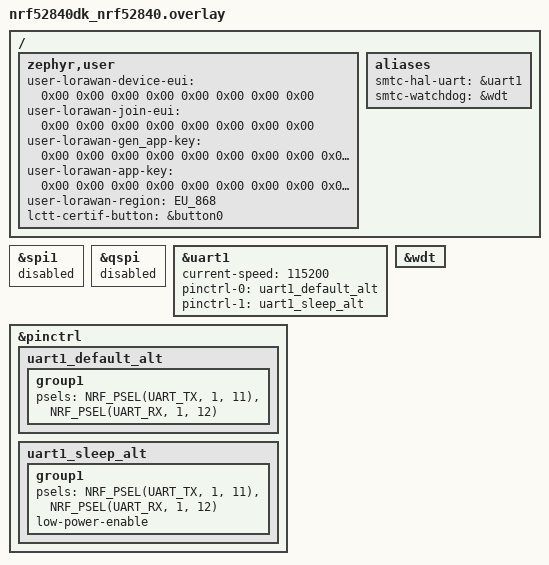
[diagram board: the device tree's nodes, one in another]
/*
 * Copyright (c) 2024 Semtech Corporation
 *
 * SPDX-License-Identifier: Apache-2.0
 */

/ {
    zephyr,user {
        user-lorawan-device-eui = <0x00 0x00 0x00 0x00 0x00 0x00 0x00 0x00>;
        user-lorawan-join-eui = <0x00 0x00 0x00 0x00 0x00 0x00 0x00 0x00>;
        user-lorawan-gen_app-key = <0x00 0x00 0x00 0x00 0x00 0x00 0x00 0x00 0x00 0x00 0x00 0x00 0x00 0x00 0x00 0x00>;
        user-lorawan-app-key = <0x00 0x00 0x00 0x00 0x00 0x00 0x00 0x00 0x00 0x00 0x00 0x00 0x00 0x00 0x00 0x00>;
        user-lorawan-region = "EU_868";

        /* PINS used for the sample. */
        lctt-certif-button = &button0;
    };

    aliases {
        /* Specify which UART is used for communication (as input for the hw modem tester) */
        smtc-hal-uart = &uart1;
        smtc-watchdog = &wdt;
    };
};

&spi1 {
    status = "disabled";
};
// &spi2 {
//     status = "disabled";
// };
&qspi {
    status = "disabled";
};

/* Specify which UART is used for communication (as input for the hw modem tester) */
&uart1 {
    status = "okay";

    current-speed = <115200>;

    pinctrl-0 = <&uart1_default_alt>;
    pinctrl-1 = <&uart1_sleep_alt>;
    pinctrl-names = "default", "sleep";
    /delete-property/ hw-flow-control;
};

&pinctrl {
    uart1_default_alt: uart1_default_alt {
        group1 {
            psels = <NRF_PSEL(UART_TX, 1, 11)>, <NRF_PSEL(UART_RX, 1, 12)>;
        };
    };

    uart1_sleep_alt: uart1_sleep_alt {
        group1 {
            psels = <NRF_PSEL(UART_TX, 1, 11)>, <NRF_PSEL(UART_RX, 1, 12)>;
            low-power-enable;
        };
    };
};

&wdt {
    status = "okay";
};
